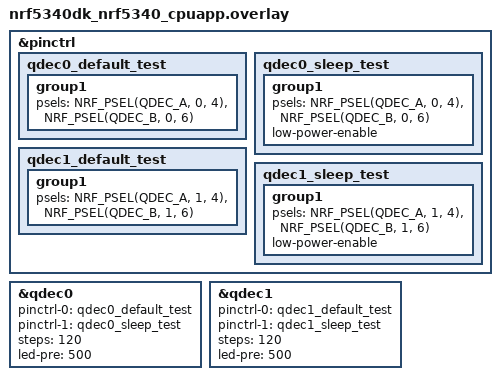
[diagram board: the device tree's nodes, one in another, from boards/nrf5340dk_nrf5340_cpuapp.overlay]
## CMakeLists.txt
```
# SPDX-License-Identifier: LicenseRef-Nordic-5-Clause

cmake_minimum_required(VERSION 3.20.0)

find_package(Zephyr REQUIRED HINTS $ENV{ZEPHYR_BASE})
project(qdec_instances)

FILE(GLOB app_sources src/*.c)
target_sources(app PRIVATE ${app_sources})
```

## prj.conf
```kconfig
CONFIG_ZTEST=y
CONFIG_TEST_USERSPACE=y
CONFIG_SENSOR=y
CONFIG_LOG=y
```

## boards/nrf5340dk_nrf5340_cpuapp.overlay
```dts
/*
 * Copyright (c) 2026 Nordic Semiconductor ASA
 *
 * SPDX-License-Identifier: LicenseRef-Nordic-5-Clause
 */

&pinctrl {
	qdec0_default_test: qdec0_default_test {
		group1 {
			psels = <NRF_PSEL(QDEC_A, 0, 4)>,
				<NRF_PSEL(QDEC_B, 0, 6)>;
		};
	};

	qdec0_sleep_test: qdec0_sleep_test {
		group1 {
			psels = <NRF_PSEL(QDEC_A, 0, 4)>,
				<NRF_PSEL(QDEC_B, 0, 6)>;
			low-power-enable;
		};
	};

	qdec1_default_test: qdec1_default_test {
		group1 {
			psels = <NRF_PSEL(QDEC_A, 1, 4)>,
				<NRF_PSEL(QDEC_B, 1, 6)>;
		};
	};

	qdec1_sleep_test: qdec1_sleep_test {
		group1 {
			psels = <NRF_PSEL(QDEC_A, 1, 4)>,
				<NRF_PSEL(QDEC_B, 1, 6)>;
			low-power-enable;
		};
	};
};

&qdec0 {
	status = "okay";
	pinctrl-0 = <&qdec0_default_test>;
	pinctrl-1 = <&qdec0_sleep_test>;
	pinctrl-names = "default", "sleep";
	steps = <120>;
	led-pre = <500>;
};

&qdec1 {
	status = "okay";
	pinctrl-0 = <&qdec1_default_test>;
	pinctrl-1 = <&qdec1_sleep_test>;
	pinctrl-names = "default", "sleep";
	steps = <120>;
	led-pre = <500>;
};
```

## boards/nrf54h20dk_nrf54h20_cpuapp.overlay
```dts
/*
 * Copyright (c) 2025 Nordic Semiconductor ASA
 *
 * SPDX-License-Identifier: LicenseRef-Nordic-5-Clause
 */

&pinctrl {
	qdec130_default_test: qdec130_default_test {
		group1 {
			psels = <NRF_PSEL(QDEC_A, 1, 1)>,
				<NRF_PSEL(QDEC_B, 1, 2)>;
		};
	};

	qdec130_sleep_test: qdec130_sleep_test {
		group1 {
			psels = <NRF_PSEL(QDEC_A, 1, 1)>,
				<NRF_PSEL(QDEC_B, 1, 2)>;
			low-power-enable;
		};
	};

	qdec131_default_test: qdec131_default_test {
		group1 {
			psels = <NRF_PSEL(QDEC_A, 2, 8)>,
				<NRF_PSEL(QDEC_B, 2, 10)>;
		};
	};

	qdec131_sleep_test: qdec131_sleep_test {
		group1 {
			psels = <NRF_PSEL(QDEC_A, 2, 8)>,
				<NRF_PSEL(QDEC_B, 2, 10)>;
			low-power-enable;
		};
	};
};

&qdec130 {
	status = "okay";
	pinctrl-0 = <&qdec130_default_test>;
	pinctrl-1 = <&qdec130_sleep_test>;
	pinctrl-names = "default", "sleep";
	steps = <120>;
	led-pre = <500>;
};

&qdec131 {
	status = "okay";
	pinctrl-0 = <&qdec131_default_test>;
	pinctrl-1 = <&qdec131_sleep_test>;
	pinctrl-names = "default", "sleep";
	steps = <120>;
	led-pre = <500>;
};
```

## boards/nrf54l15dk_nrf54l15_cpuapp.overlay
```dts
/*
 * Copyright (c) 2025 Nordic Semiconductor ASA
 *
 * SPDX-License-Identifier: LicenseRef-Nordic-5-Clause
 */

&pinctrl {
	qdec20_default_test: qdec20_default_test {
		group1 {
			psels = <NRF_PSEL(QDEC_A, 1, 8)>,
				<NRF_PSEL(QDEC_B, 1, 10)>;
		};
	};

	qdec20_sleep_test: qdec20_sleep_test {
		group1 {
			psels = <NRF_PSEL(QDEC_A, 1, 8)>,
				<NRF_PSEL(QDEC_B, 1, 10)>;
			low-power-enable;
		};
	};

	qdec21_default_test: qdec21_default_test {
		group1 {
			psels = <NRF_PSEL(QDEC_A, 1, 12)>,
				<NRF_PSEL(QDEC_B, 1, 14)>;
		};
	};

	qdec21_sleep_test: qdec21_sleep_test {
		group1 {
			psels = <NRF_PSEL(QDEC_A, 1, 12)>,
				<NRF_PSEL(QDEC_B, 1, 14)>;
			low-power-enable;
		};
	};
};

&qdec20 {
	status = "okay";
	pinctrl-0 = <&qdec20_default_test>;
	pinctrl-1 = <&qdec20_sleep_test>;
	pinctrl-names = "default", "sleep";
	steps = <120>;
	led-pre = <500>;
};

&qdec21 {
	status = "okay";
	pinctrl-0 = <&qdec21_default_test>;
	pinctrl-1 = <&qdec21_sleep_test>;
	pinctrl-names = "default", "sleep";
	steps = <120>;
	led-pre = <500>;
};
```

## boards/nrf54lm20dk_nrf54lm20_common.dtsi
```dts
/*
 * Copyright (c) 2026 Nordic Semiconductor ASA
 *
 * SPDX-License-Identifier: LicenseRef-Nordic-5-Clause
 */

&pinctrl {
	qdec20_default_test: qdec20_default_test {
		group1 {
			psels = <NRF_PSEL(QDEC_A, 1, 3)>,
				<NRF_PSEL(QDEC_B, 1, 30)>;
		};
	};

	qdec20_sleep_test: qdec20_sleep_test {
		group1 {
			psels = <NRF_PSEL(QDEC_A, 1, 3)>,
				<NRF_PSEL(QDEC_B, 1, 30)>;
			low-power-enable;
		};
	};

	qdec21_default_test: qdec21_default_test {
		group1 {
			psels = <NRF_PSEL(QDEC_A, 1, 23)>,
				<NRF_PSEL(QDEC_B, 1, 13)>;
		};
	};

	qdec21_sleep_test: qdec21_sleep_test {
		group1 {
			psels = <NRF_PSEL(QDEC_A, 1, 23)>,
				<NRF_PSEL(QDEC_B, 1, 13)>;
			low-power-enable;
		};
	};
};

&qdec20 {
	status = "okay";
	pinctrl-0 = <&qdec20_default_test>;
	pinctrl-1 = <&qdec20_sleep_test>;
	pinctrl-names = "default", "sleep";
	steps = <127>;
	led-pre = <500>;
};

&qdec21 {
	status = "okay";
	pinctrl-0 = <&qdec21_default_test>;
	pinctrl-1 = <&qdec21_sleep_test>;
	pinctrl-names = "default", "sleep";
	steps = <127>;
	led-pre = <500>;
};
```

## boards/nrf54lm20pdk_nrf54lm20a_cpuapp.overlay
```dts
/*
 * Copyright (c) 2025 Nordic Semiconductor ASA
 *
 * SPDX-License-Identifier: LicenseRef-Nordic-5-Clause
 */

&pinctrl {
	qdec20_default_test: qdec20_default_test {
		group1 {
			psels = <NRF_PSEL(QDEC_A, 1, 3)>,
				<NRF_PSEL(QDEC_B, 1, 30)>;
		};
	};

	qdec20_sleep_test: qdec20_sleep_test {
		group1 {
			psels = <NRF_PSEL(QDEC_A, 1, 3)>,
				<NRF_PSEL(QDEC_B, 1, 30)>;
			low-power-enable;
		};
	};

	qdec21_default_test: qdec21_default_test {
		group1 {
			psels = <NRF_PSEL(QDEC_A, 1, 18)>,
				<NRF_PSEL(QDEC_B, 1, 15)>;
		};
	};

	qdec21_sleep_test: qdec21_sleep_test {
		group1 {
			psels = <NRF_PSEL(QDEC_A, 1, 18)>,
				<NRF_PSEL(QDEC_B, 1, 15)>;
			low-power-enable;
		};
	};
};

&qdec20 {
	status = "okay";
	pinctrl-0 = <&qdec20_default_test>;
	pinctrl-1 = <&qdec20_sleep_test>;
	pinctrl-names = "default", "sleep";
	steps = <127>;
	led-pre = <500>;
};

&qdec21 {
	status = "okay";
	pinctrl-0 = <&qdec21_default_test>;
	pinctrl-1 = <&qdec21_sleep_test>;
	pinctrl-names = "default", "sleep";
	steps = <127>;
	led-pre = <500>;
};
```

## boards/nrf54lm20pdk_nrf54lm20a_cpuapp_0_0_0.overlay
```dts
/*
 * Copyright (c) 2025 Nordic Semiconductor ASA
 *
 * SPDX-License-Identifier: LicenseRef-Nordic-5-Clause
 */

&pinctrl {
	qdec20_default_test: qdec20_default_test {
		group1 {
			psels = <NRF_PSEL(QDEC_A, 1, 0)>,
				<NRF_PSEL(QDEC_B, 1, 2)>;
		};
	};

	qdec20_sleep_test: qdec20_sleep_test {
		group1 {
			psels = <NRF_PSEL(QDEC_A, 1, 0)>,
				<NRF_PSEL(QDEC_B, 1, 2)>;
			low-power-enable;
		};
	};

	qdec21_default_test: qdec21_default_test {
		group1 {
			psels = <NRF_PSEL(QDEC_A, 1, 12)>,
				<NRF_PSEL(QDEC_B, 1, 13)>;
		};
	};

	qdec21_sleep_test: qdec21_sleep_test {
		group1 {
			psels = <NRF_PSEL(QDEC_A, 1, 12)>,
				<NRF_PSEL(QDEC_B, 1, 13)>;
			low-power-enable;
		};
	};
};

&qdec20 {
	status = "okay";
	pinctrl-0 = <&qdec20_default_test>;
	pinctrl-1 = <&qdec20_sleep_test>;
	pinctrl-names = "default", "sleep";
	steps = <127>;
	led-pre = <500>;
};

&qdec21 {
	status = "okay";
	pinctrl-0 = <&qdec21_default_test>;
	pinctrl-1 = <&qdec21_sleep_test>;
	pinctrl-names = "default", "sleep";
	steps = <127>;
	led-pre = <500>;
};
```

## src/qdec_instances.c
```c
/*
 * Copyright (c) 2025, Nordic Semiconductor ASA
 *
 * SPDX-License-Identifier: LicenseRef-Nordic-5-Clause
 */

#include <zephyr/kernel.h>
#include <zephyr/drivers/sensor.h>
#include <zephyr/ztest.h>
#include <zephyr/pm/device_runtime.h>

#include <zephyr/logging/log.h>
LOG_MODULE_REGISTER(test);

#define DEVICE_DT_GET_AND_COMMA(node_id) DEVICE_DT_GET(node_id),
/* Generate a list of devices for all instances of the "compat" */
#define DEVS_FOR_DT_COMPAT(compat) \
	DT_FOREACH_STATUS_OKAY(compat, DEVICE_DT_GET_AND_COMMA)

static const struct device *const devices[] = {
#ifdef CONFIG_NRFX_QDEC
	DEVS_FOR_DT_COMPAT(nordic_nrf_qdec)
#endif
};

typedef void (*test_func_t)(const struct device *dev);
typedef bool (*capability_func_t)(const struct device *dev);

static void setup_instance(const struct device *dev)
{
	pm_device_runtime_get(dev);
}

static void tear_down_instance(const struct device *dev)
{
	pm_device_runtime_put(dev);
}

static void test_all_instances(test_func_t func, capability_func_t capability_check)
{
	int devices_skipped = 0;

	zassert_true(ARRAY_SIZE(devices) > 0, "No device found");
	for (int i = 0; i < ARRAY_SIZE(devices); i++) {
		setup_instance(devices[i]);
		TC_PRINT("\nInstance %u: ", i + 1);
		if ((capability_check == NULL) ||
		     capability_check(devices[i])) {
			TC_PRINT("Testing %s\n", devices[i]->name);
			func(devices[i]);
		} else {
			TC_PRINT("Skipped for %s\n", devices[i]->name);
			devices_skipped++;
		}
		tear_down_instance(devices[i]);
		/* Allow logs to be printed. */
		k_sleep(K_MSEC(100));
	}
	if (devices_skipped == ARRAY_SIZE(devices)) {
		ztest_test_skip();
	}
}


/**
 * Test validates if instance can fetch sample.
 */
static void test_sensor_sample_fetch_instance(const struct device *dev)
{
	struct sensor_value val;
	int ret = 0;

	ret = sensor_sample_fetch(dev);
	zassert_equal(0, ret, "%s: sensor_sample_fetch() failed", dev->name);

	ret = sensor_channel_get(dev, SENSOR_CHAN_ROTATION, &val);
	zassert_equal(0, ret, "%s: sensor_channel_get() failed", dev->name);

	TC_PRINT("Position = %d degrees\n", val.val1);
}

static bool test_sensor_sample_fetch_capable(const struct device *dev)
{
	return true;
}

ZTEST(qdec_instances, test_sensor_sample_fetch)
{
	test_all_instances(test_sensor_sample_fetch_instance, test_sensor_sample_fetch_capable);
}

static void *suite_setup(void)
{
	int i;

	for (i = 0; i < ARRAY_SIZE(devices); i++) {
		zassert_true(device_is_ready(devices[i]),
			     "Device %s is not ready", devices[i]->name);
		k_object_access_grant(devices[i], k_current_get());
	}

	return NULL;
}

ZTEST_SUITE(qdec_instances, NULL, suite_setup, NULL, NULL, NULL);
```
